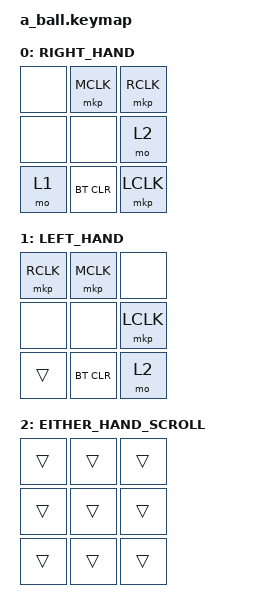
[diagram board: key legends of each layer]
#include <behaviors.dtsi>
#include <dt-bindings/zmk/keys.h>
#include <dt-bindings/zmk/bt.h>
//#include <dt-bindings/zmk/mouse.h>

#include <dt-bindings/zmk/outputs.h>
#include <dt-bindings/zmk/mouse.h>
#include <dt-bindings/zmk/ext_power.h>
//#include <behaviors/mouse_keys.dtsi>
//#include <input/processors.dtsi>


#define DEFAULT 0

// Mouse speed increased
#define ZMK_POINTING_DEFAULT_MOVE_VAL 1000  // default: 600
#define ZMK_POINTING_DEFAULT_SCRL_VAL 15    // default: 10
//#include <dt-bindings/zmk/pointing.h>

// #define LEFT_HAND     	0
// #define RIGHT_HAND     	1
// #define EITHER_HAND_SCROLL	2

/ {
    keymap {
        compatible = "zmk,keymap";
// Map is not exactly a 3x3 matrix, close enough to treat it like that:
//         map = <
// Row 0:
//	               RC(0,0) RC(0,1) RC(0,2) 
// Row 1:
//                   RC(0,6)                 RC(0,5) 
//
//                                             RC(0,3) 
//
// Row 2:
//                              RC(0,7) RC(0,8)   
//
//					       RC(0,4)       
//        >;
// &mkp LCLK &mkp MCLK &mkp RCLK  &none
        RIGHT_HAND {
            bindings = <
                       &none&mkp MCLK &mkp RCLK
                  &none                          &none
                                                    &mo 2
                		&mo 1 &bt BT_CLR
						    &mkp LCLK 
            >;
        };

	// Left hand layer swaps the left and right buttons, and indicates to trakball_listener that it should swap X and Y axis (from those set by default.)
        LEFT_HAND {
            bindings = <
                       &mkp RCLK &mkp MCLK  &none
                  &none                          &none
                                                    &mkp LCLK
                		&trans &bt BT_CLR
						    &mo 2 
            >;
        };

	// Scroll layers do nothing by themselves, but indicate to trackball_listener that it should apply the appropriate transformation, i.e. switch to scrolling instead of pointing.
	// For that reason it is completely transparent.
        EITHER_HAND_SCROLL {
            bindings = <
		&trans	&trans	&trans
		&trans	&trans	&trans
		&trans	&trans	&trans
            >;
        };


    };

};
